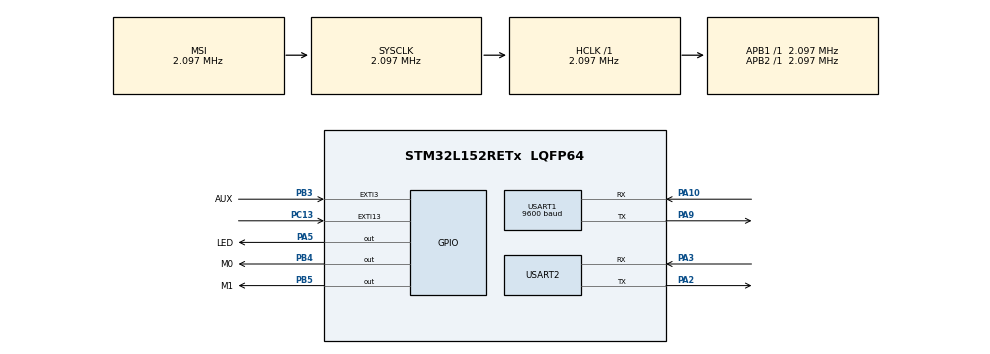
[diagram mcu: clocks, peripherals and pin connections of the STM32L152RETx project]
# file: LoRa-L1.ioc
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Mcu.Family=STM32L1
Mcu.Name=STM32L152RETx
Mcu.Package=LQFP64
NVIC.EXTI15_10_IRQn=true\:0\:0\:false\:false\:true\:true\:true\:true
NVIC.EXTI3_IRQn=true\:0\:0\:false\:false\:true\:true\:true\:true
NVIC.PriorityGroup=NVIC_PRIORITYGROUP_4
NVIC.USART1_IRQn=true\:0\:0\:false\:false\:true\:true\:true\:true
NVIC.USART2_IRQn=true\:0\:0\:false\:false\:true\:true\:true\:true
PA10.GPIO_ModeDefaultPP=GPIO_MODE_AF_OD
PA10.Mode=Asynchronous
PA10.Signal=USART1_RX
PA2.GPIO_ModeDefaultPP=GPIO_MODE_AF_PP
PA2.Mode=Asynchronous
PA2.Signal=USART2_TX
PA3.GPIO_ModeDefaultPP=GPIO_MODE_AF_PP
PA3.Mode=Asynchronous
PA3.Signal=USART2_RX
PA5.GPIO_Label=LED
PA5.PinState=GPIO_PIN_SET
PA5.Signal=GPIO_Output
PA9.GPIO_ModeDefaultPP=GPIO_MODE_AF_OD
PA9.Mode=Asynchronous
PA9.Signal=USART1_TX
PB3.GPIO_Label=AUX
PB3.GPIO_ModeDefaultEXTI=GPIO_MODE_IT_RISING_FALLING
PB3.Signal=GPXTI3
PB4.GPIO_Label=M0
PB4.GPIO_PuPd=GPIO_PULLUP
PB4.Signal=GPIO_Output
PB5.GPIO_Label=M1
PB5.GPIO_PuPd=GPIO_PULLUP
PB5.Signal=GPIO_Output
PC13-WKUP2.Signal=GPXTI13
ProjectManager.HeapSize=0x200
ProjectManager.StackSize=0x400
ProjectManager.TargetToolchain=STM32CubeIDE
RCC.48MHZClocksFreq_Value=24000000
RCC.AHBFreq_Value=2097000
RCC.APB1Freq_Value=2097000
RCC.APB1TimFreq_Value=2097000
RCC.APB2Freq_Value=2097000
RCC.APB2TimFreq_Value=2097000
RCC.HCLKFreq_Value=2097000
RCC.HSE_VALUE=24000000
RCC.HSI_VALUE=16000000
RCC.LSE_VALUE=32768
RCC.MSI_VALUE=2097000
RCC.SYSCLKFreq_VALUE=2097000
RCC.VCOOutputFreq_Value=48000000
USART1.BaudRate=9600
USART1.VirtualMode=VM_ASYNC
USART2.VirtualMode=VM_ASYNC
board=custom

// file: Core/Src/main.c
/* USER CODE BEGIN Header */
/**
  ******************************************************************************
  * @file           : main.c
  * @brief          : Main program body
  ******************************************************************************
  * @attention
  *
  * Copyright (c) 2026 STMicroelectronics.
  * All rights reserved.
  *
  * This software is licensed under terms that can be found in the LICENSE file
  * in the root directory of this software component.
  * If no LICENSE file comes with this software, it is provided AS-IS.
  *
  ******************************************************************************
  */
/* USER CODE END Header */
#include "main.h"

/* USER CODE BEGIN Includes */
#include "LoRa.h"
#include "Mesh.h"
/* USER CODE END Includes */

UART_HandleTypeDef huart1;
UART_HandleTypeDef huart2;

void SystemClock_Config(void);
static void MX_GPIO_Init(void);
static void MX_USART1_UART_Init(void);
static void MX_USART2_UART_Init(void);

/* USER CODE BEGIN 0 */
//uint8_t rx_data_to_send[512] = {0};
//uint8_t rx_buffer[512] = {0};
//uint8_t rx_byte;
//uint8_t rx_index = 0;
/* USER CODE END 0 */

int main(void)
{

  /* MCU Configuration--------------------------------------------------------*/

  /* Reset of all peripherals, Initializes the Flash interface and the Systick. */
  HAL_Init();

  /* Configure the system clock */
  SystemClock_Config();

  /* Initialize all configured peripherals */
  MX_GPIO_Init();
  MX_USART1_UART_Init();
  MX_USART2_UART_Init();
  /* USER CODE BEGIN 2 */

  LoRa_Init(&huart1, &huart2);
//  LoRa_Set_Address(0x00AA); 	// For the first module - black wire STML1
//  LoRa_Set_Address(0x00BB); 	// For the second module - white wire STML1
//  LoRa_Set_Address(0x00CC); 	// For the third module - black wire STML4

//  LoRa_Set_NetID(0x00EE);
//
//  LoRa_Set_SerialPortRate(SPR_9600);
//  LoRa_Set_SerialParityBit(SPB_8N1);
//  LoRa_Set_AirDataRate(ADR_2_4K);
//
//  LoRa_Set_SubPacketSetting(SPS_32);
//  LoRa_Set_RSSIAmbientNoise(DISABLE);
//  LoRa_Set_TransmittingPower(TP_22DBM);
//
//  LoRa_Set_Channel(18);
//
//  LoRa_Set_RSSIEnable(DISABLE);
//  LoRa_Set_TransmissionMode(TM_TRANSPARENT);
//  LoRa_Set_ReplyEnable(DISABLE);
//  LoRa_Set_LBTEnable(DISABLE);
//  LoRa_Set_WORTransceiverControl(WOR_RECEIVER);
//  LoRa_Set_WORCycle(CYCLE_2000MS);
//
//  LoRa_Set_Encryption(0xFEED);
  /* USER CODE END 2 */

  /* Infinite loop */
  /* USER CODE BEGIN WHILE */

  LoRa_ModeSelect(MODE_NORMAL);
  while (1)
  {

    /* USER CODE END WHILE */

  }
}

void SystemClock_Config(void)
{
  RCC_OscInitTypeDef RCC_OscInitStruct = {0};
  RCC_ClkInitTypeDef RCC_ClkInitStruct = {0};

  /** Configure the main internal regulator output voltage
  */
  __HAL_PWR_VOLTAGESCALING_CONFIG(PWR_REGULATOR_VOLTAGE_SCALE1);

  /** Initializes the RCC Oscillators according to the specified parameters
  * in the RCC_OscInitTypeDef structure.
  */
  RCC_OscInitStruct.OscillatorType = RCC_OSCILLATORTYPE_MSI;
  RCC_OscInitStruct.MSIState = RCC_MSI_ON;
  RCC_OscInitStruct.MSICalibrationValue = 0;
  RCC_OscInitStruct.MSIClockRange = RCC_MSIRANGE_5;
  RCC_OscInitStruct.PLL.PLLState = RCC_PLL_NONE;
  if (HAL_RCC_OscConfig(&RCC_OscInitStruct) != HAL_OK)
  {
    Error_Handler();
  }

  /** Initializes the CPU, AHB and APB buses clocks
  */
  RCC_ClkInitStruct.ClockType = RCC_CLOCKTYPE_HCLK|RCC_CLOCKTYPE_SYSCLK
                              |RCC_CLOCKTYPE_PCLK1|RCC_CLOCKTYPE_PCLK2;
  RCC_ClkInitStruct.SYSCLKSource = RCC_SYSCLKSOURCE_MSI;
  RCC_ClkInitStruct.AHBCLKDivider = RCC_SYSCLK_DIV1;
  RCC_ClkInitStruct.APB1CLKDivider = RCC_HCLK_DIV1;
  RCC_ClkInitStruct.APB2CLKDivider = RCC_HCLK_DIV1;

  if (HAL_RCC_ClockConfig(&RCC_ClkInitStruct, FLASH_LATENCY_0) != HAL_OK)
  {
    Error_Handler();
  }
}

static void MX_USART1_UART_Init(void)
{

  huart1.Instance = USART1;
  huart1.Init.BaudRate = 9600;
  huart1.Init.WordLength = UART_WORDLENGTH_8B;
  huart1.Init.StopBits = UART_STOPBITS_1;
  huart1.Init.Parity = UART_PARITY_NONE;
  huart1.Init.Mode = UART_MODE_TX_RX;
  huart1.Init.HwFlowCtl = UART_HWCONTROL_NONE;
  huart1.Init.OverSampling = UART_OVERSAMPLING_16;
  if (HAL_UART_Init(&huart1) != HAL_OK)
  {
    Error_Handler();
  }

}

static void MX_USART2_UART_Init(void)
{

  huart2.Instance = USART2;
  huart2.Init.BaudRate = 115200;
  huart2.Init.WordLength = UART_WORDLENGTH_8B;
  huart2.Init.StopBits = UART_STOPBITS_1;
  huart2.Init.Parity = UART_PARITY_NONE;
  huart2.Init.Mode = UART_MODE_TX_RX;
  huart2.Init.HwFlowCtl = UART_HWCONTROL_NONE;
  huart2.Init.OverSampling = UART_OVERSAMPLING_16;
  if (HAL_UART_Init(&huart2) != HAL_OK)
  {
    Error_Handler();
  }

}

static void MX_GPIO_Init(void)
{
  GPIO_InitTypeDef GPIO_InitStruct = {0};

  /* GPIO Ports Clock Enable */
  __HAL_RCC_GPIOC_CLK_ENABLE();
  __HAL_RCC_GPIOA_CLK_ENABLE();
  __HAL_RCC_GPIOB_CLK_ENABLE();

  /*Configure GPIO pin Output Level */
  HAL_GPIO_WritePin(LED_GPIO_Port, LED_Pin, GPIO_PIN_SET);

  /*Configure GPIO pin Output Level */
  HAL_GPIO_WritePin(GPIOB, M0_Pin|M1_Pin, GPIO_PIN_RESET);

  /*Configure GPIO pin : PC13 */
  GPIO_InitStruct.Pin = GPIO_PIN_13;
  GPIO_InitStruct.Mode = GPIO_MODE_IT_RISING;
  GPIO_InitStruct.Pull = GPIO_NOPULL;
  HAL_GPIO_Init(GPIOC, &GPIO_InitStruct);

  /*Configure GPIO pin : LED_Pin */
  GPIO_InitStruct.Pin = LED_Pin;
  GPIO_InitStruct.Mode = GPIO_MODE_OUTPUT_PP;
  GPIO_InitStruct.Pull = GPIO_NOPULL;
  GPIO_InitStruct.Speed = GPIO_SPEED_FREQ_LOW;
  HAL_GPIO_Init(LED_GPIO_Port, &GPIO_InitStruct);

  /*Configure GPIO pin : AUX_Pin */
  GPIO_InitStruct.Pin = AUX_Pin;
  GPIO_InitStruct.Mode = GPIO_MODE_IT_RISING_FALLING;
  GPIO_InitStruct.Pull = GPIO_NOPULL;
  HAL_GPIO_Init(AUX_GPIO_Port, &GPIO_InitStruct);

  /*Configure GPIO pins : M0_Pin M1_Pin */
  GPIO_InitStruct.Pin = M0_Pin|M1_Pin;
  GPIO_InitStruct.Mode = GPIO_MODE_OUTPUT_PP;
  GPIO_InitStruct.Pull = GPIO_PULLUP;
  GPIO_InitStruct.Speed = GPIO_SPEED_FREQ_LOW;
  HAL_GPIO_Init(GPIOB, &GPIO_InitStruct);

  /* EXTI interrupt init*/
  HAL_NVIC_SetPriority(EXTI3_IRQn, 0, 0);
  HAL_NVIC_EnableIRQ(EXTI3_IRQn);

  HAL_NVIC_SetPriority(EXTI15_10_IRQn, 0, 0);
  HAL_NVIC_EnableIRQ(EXTI15_10_IRQn);

}

void Error_Handler(void)
{
  __disable_irq();
  while (1)
  {
  }
}
